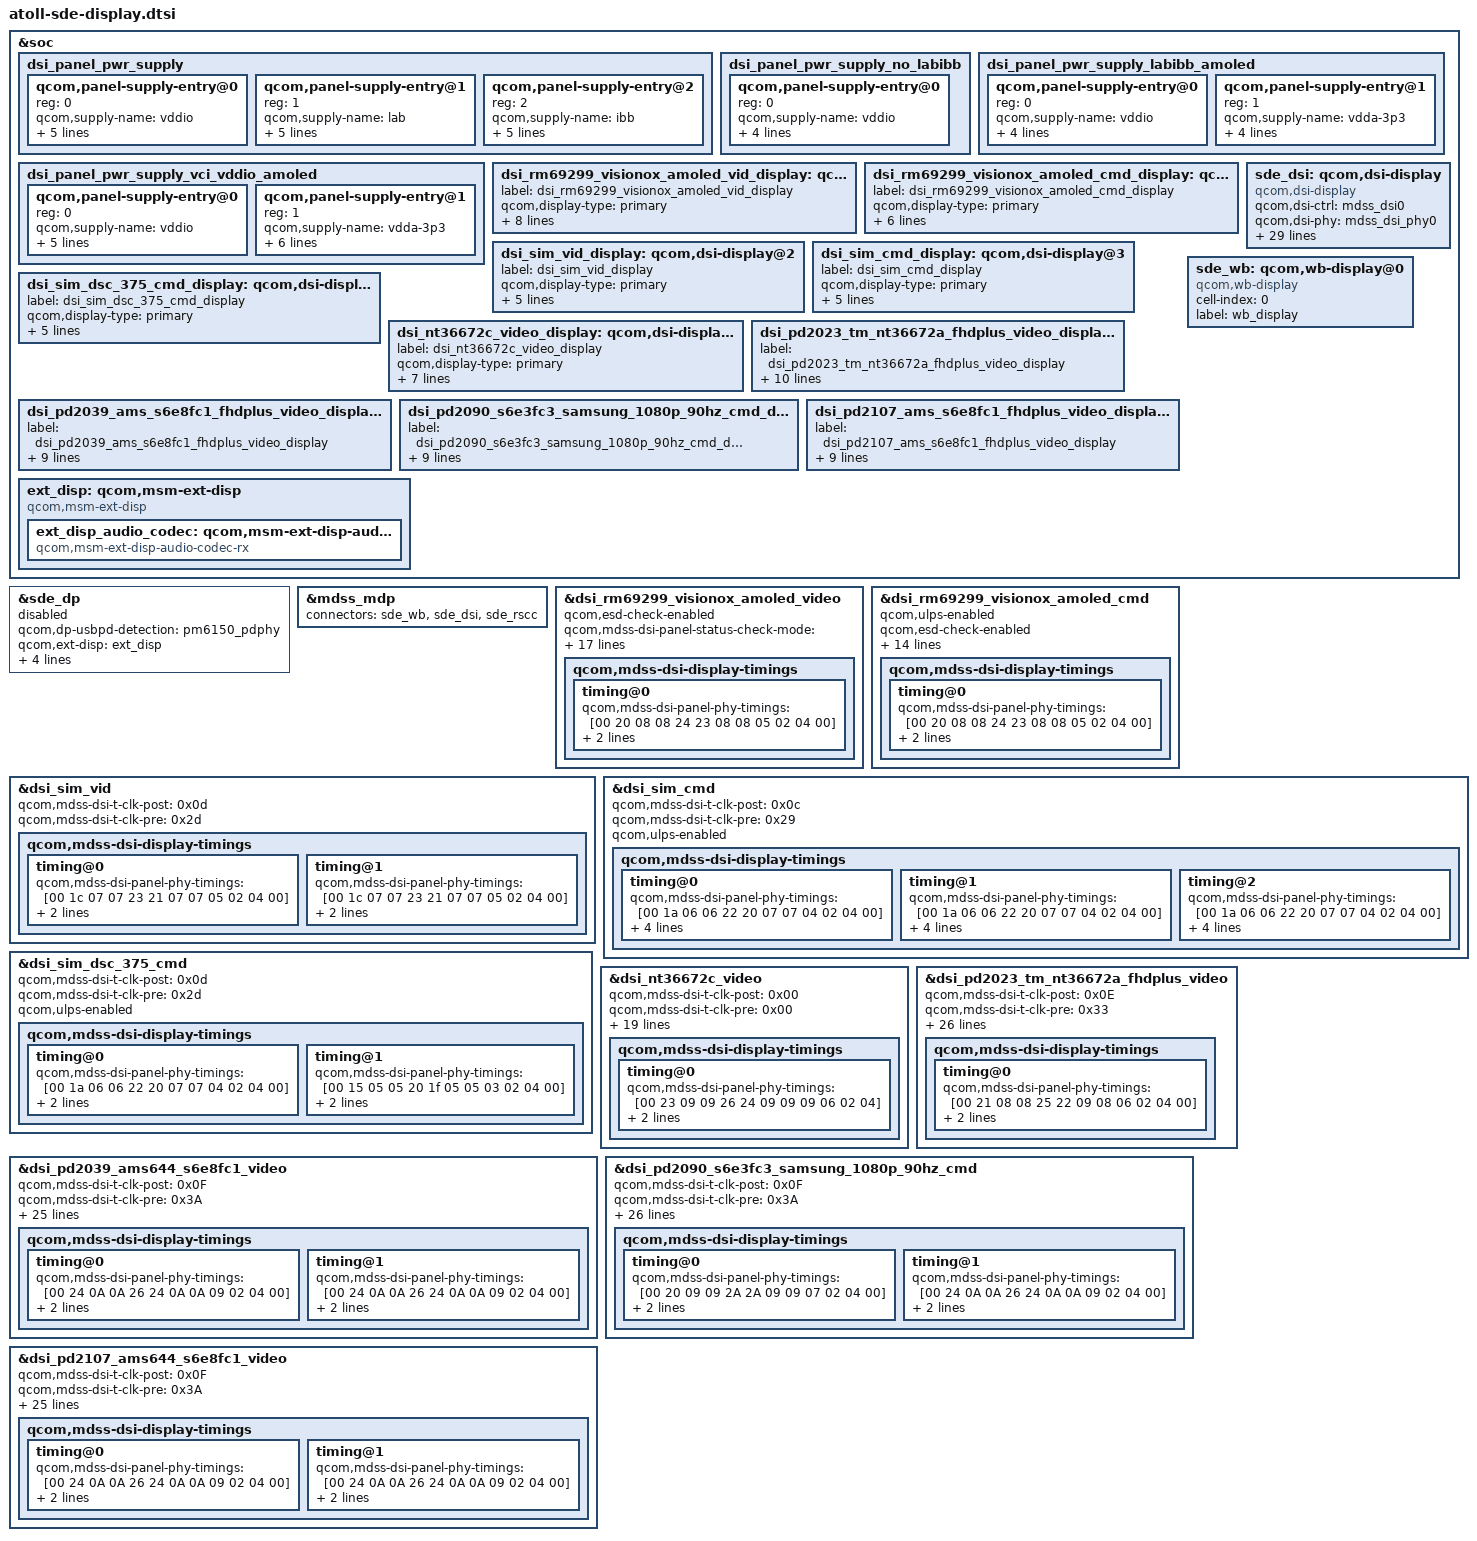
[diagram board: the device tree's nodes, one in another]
/* Copyright (c) 2019-2020, The Linux Foundation. All rights reserved.
 *
 * This program is free software; you can redistribute it and/or modify
 * it under the terms of the GNU General Public License version 2 and
 * only version 2 as published by the Free Software Foundation.
 *
 * This program is distributed in the hope that it will be useful,
 * but WITHOUT ANY WARRANTY; without even the implied warranty of
 * MERCHANTABILITY or FITNESS FOR A PARTICULAR PURPOSE.  See the
 * GNU General Public License for more details.
 */

#include "dsi-panel-rm69299-visionox-amoled-fhd-plus-video.dtsi"
#include "dsi-panel-rm69299-visionox-amoled-fhd-plus-cmd.dtsi"
#include "dsi-panel-sim-video.dtsi"
#include "dsi-panel-sim-cmd.dtsi"
#include "dsi-panel-sim-dsc375-cmd.dtsi"
#include "dsi-panel-nt36672c-fhd-plus-video.dtsi"
#include "dsi-panel-pd2023-tm-nt36672a-fhdplus-video.dtsi"
#include "dsi-panel-pd2039-ams644-s6e8fc1-1080p-video.dtsi"
#include "dsi-panel-pd2090-s6e3fc3-samsung-1080p-cmd.dtsi"
#include "dsi-panel-pd2107-ams644-s6e8fc1-1080p-video.dtsi"
#include <dt-bindings/clock/mdss-10nm-pll-clk.h>

&soc {
	dsi_panel_pwr_supply: dsi_panel_pwr_supply {
		#address-cells = <1>;
		#size-cells = <0>;

		qcom,panel-supply-entry@0 {
			reg = <0>;
			qcom,supply-name = "vddio";
			qcom,supply-min-voltage = <1800000>;
			qcom,supply-max-voltage = <1904000>;
			qcom,supply-enable-load = <32000>;
			qcom,supply-disable-load = <80>;
		};

		qcom,panel-supply-entry@1 {
			reg = <1>;
			qcom,supply-name = "lab";
			qcom,supply-min-voltage = <4600000>;
			qcom,supply-max-voltage = <6000000>;
			qcom,supply-enable-load = <100000>;
			qcom,supply-disable-load = <100>;
		};

		qcom,panel-supply-entry@2 {
			reg = <2>;
			qcom,supply-name = "ibb";
			qcom,supply-min-voltage = <4600000>;
			qcom,supply-max-voltage = <6000000>;
			qcom,supply-enable-load = <100000>;
			qcom,supply-disable-load = <100>;
			qcom,supply-post-on-sleep = <20>;
		};
	};

	dsi_panel_pwr_supply_no_labibb: dsi_panel_pwr_supply_no_labibb {
		#address-cells = <1>;
		#size-cells = <0>;

		qcom,panel-supply-entry@0 {
			reg = <0>;
			qcom,supply-name = "vddio";
			qcom,supply-min-voltage = <1800000>;
			qcom,supply-max-voltage = <1904000>;
			qcom,supply-enable-load = <32000>;
			qcom,supply-disable-load = <80>;
		};
	};

	dsi_panel_pwr_supply_labibb_amoled: dsi_panel_pwr_supply_labibb_amoled {
		#address-cells = <1>;
		#size-cells = <0>;

		qcom,panel-supply-entry@0 {
			reg = <0>;
			qcom,supply-name = "vddio";
			qcom,supply-min-voltage = <1800000>;
			qcom,supply-max-voltage = <1904000>;
			qcom,supply-enable-load = <32000>;
			qcom,supply-disable-load = <80>;
		};

		qcom,panel-supply-entry@1 {
			reg = <1>;
			qcom,supply-name = "vdda-3p3";
			qcom,supply-min-voltage = <3000000>;
			qcom,supply-max-voltage = <3000000>;
			qcom,supply-enable-load = <13200>;
			qcom,supply-disable-load = <80>;
		};
	};

	dsi_panel_pwr_supply_vci_vddio_amoled: dsi_panel_pwr_supply_vci_vddio_amoled {
		#address-cells = <1>;
		#size-cells = <0>;

		qcom,panel-supply-entry@0 {
			reg = <0>;
			qcom,supply-name = "vddio";
			qcom,supply-min-voltage = <1800000>;
			qcom,supply-max-voltage = <1800000>;
			qcom,supply-enable-load = <32000>;
			qcom,supply-disable-load = <80>;
			qcom,supply-post-on-sleep = <5>;
		};

		qcom,panel-supply-entry@1 {
			reg = <1>;
			qcom,supply-name = "vdda-3p3";
			qcom,supply-min-voltage = <3100000>;
			qcom,supply-max-voltage = <3100000>;
			qcom,supply-enable-load = <13200>;
			qcom,supply-disable-load = <80>;
			qcom,supply-post-on-sleep = <12>;
			qcom,supply-pre-off-sleep = <3>;
		};
	};


	dsi_rm69299_visionox_amoled_vid_display: qcom,dsi-display@0 {
		label = "dsi_rm69299_visionox_amoled_vid_display";
		qcom,display-type = "primary";

		qcom,dsi-ctrl-num = <0>;
		qcom,dsi-phy-num = <0>;
		qcom,dsi-select-clocks = "mux_byte_clk0", "mux_pixel_clk0",
				"src_byte_clk0", "src_pixel_clk0",
				"shadow_byte_clk0", "shadow_pixel_clk0";

		qcom,dsi-panel = <&dsi_rm69299_visionox_amoled_video>;
	};

	dsi_rm69299_visionox_amoled_cmd_display: qcom,dsi-display@1 {
		label = "dsi_rm69299_visionox_amoled_cmd_display";
		qcom,display-type = "primary";
		qcom,dsi-ctrl-num = <0>;
		qcom,dsi-phy-num = <0>;
		qcom,dsi-select-clocks = "mux_byte_clk0", "mux_pixel_clk0";
		qcom,dsi-panel = <&dsi_rm69299_visionox_amoled_cmd>;
	};

	dsi_sim_vid_display: qcom,dsi-display@2 {
		label = "dsi_sim_vid_display";
		qcom,display-type = "primary";

		qcom,dsi-ctrl-num = <0>;
		qcom,dsi-phy-num = <0>;
		qcom,dsi-select-clocks = "mux_byte_clk0", "mux_pixel_clk0";

		qcom,dsi-panel = <&dsi_sim_vid>;
	};

	dsi_sim_cmd_display: qcom,dsi-display@3 {
		label = "dsi_sim_cmd_display";
		qcom,display-type = "primary";

		qcom,dsi-ctrl-num = <0>;
		qcom,dsi-phy-num = <0>;
		qcom,dsi-select-clocks = "mux_byte_clk0", "mux_pixel_clk0";

		qcom,dsi-panel = <&dsi_sim_cmd>;
	};

	dsi_sim_dsc_375_cmd_display: qcom,dsi-display@4 {
		label = "dsi_sim_dsc_375_cmd_display";
		qcom,display-type = "primary";

		qcom,dsi-ctrl-num = <0>;
		qcom,dsi-phy-num = <0>;
		qcom,dsi-select-clocks = "mux_byte_clk0", "mux_pixel_clk0";

		qcom,dsi-panel = <&dsi_sim_dsc_375_cmd>;
	};

	dsi_nt36672c_video_display: qcom,dsi-display@5 {
		label = "dsi_nt36672c_video_display";
		qcom,display-type = "primary";

		qcom,dsi-ctrl-num = <0>;
		qcom,dsi-phy-num = <0>;

		qcom,dsi-select-clocks = "mux_byte_clk0", "mux_pixel_clk0",
					"cphy_byte_clk0", "cphy_pixel_clk0",
					"shadow_cphybyte_clk0",
					"shadow_cphypixel_clk0";
		qcom,dsi-panel = <&dsi_nt36672c_video>;
	};

	dsi_pd2023_tm_nt36672a_fhdplus_video_display: qcom,dsi-display@6 {
		label = "dsi_pd2023_tm_nt36672a_fhdplus_video_display";
		qcom,display-type = "primary";

		qcom,dsi-ctrl-num = <0>;
		qcom,dsi-phy-num = <0>;

		qcom,dsi-select-clocks = "mux_byte_clk0", "mux_pixel_clk0",
							"src_byte_clk0", "src_pixel_clk0",
							"shadow_byte_clk0", "shadow_pixel_clk0";
		qcom,dsi-panel = <&dsi_pd2023_tm_nt36672a_fhdplus_video>;
	};

	dsi_pd2039_ams_s6e8fc1_fhdplus_video_display: qcom,dsi-display@10 {
		label = "dsi_pd2039_ams_s6e8fc1_fhdplus_video_display";
		qcom,display-type = "primary";

		qcom,dsi-ctrl-num = <0>;
		qcom,dsi-phy-num = <0>;
		qcom,dsi-select-clocks = "mux_byte_clk0", "mux_pixel_clk0",
							"src_byte_clk0", "src_pixel_clk0",
							"shadow_byte_clk0", "shadow_pixel_clk0";

		qcom,dsi-panel = <&dsi_pd2039_ams644_s6e8fc1_video>;
	};
	dsi_pd2090_s6e3fc3_samsung_1080p_90hz_cmd_display: qcom,dsi-display@11 {
		label = "dsi_pd2090_s6e3fc3_samsung_1080p_90hz_cmd_display";
		qcom,display-type = "primary";

		qcom,dsi-ctrl-num = <0>;
		qcom,dsi-phy-num = <0>;
		qcom,dsi-select-clocks = "mux_byte_clk0", "mux_pixel_clk0",
							"src_byte_clk0", "src_pixel_clk0",
							"shadow_byte_clk0", "shadow_pixel_clk0";

		qcom,dsi-panel = <&dsi_pd2090_s6e3fc3_samsung_1080p_90hz_cmd>;
	};

	dsi_pd2107_ams_s6e8fc1_fhdplus_video_display: qcom,dsi-display@12 {
		label = "dsi_pd2107_ams_s6e8fc1_fhdplus_video_display";
		qcom,display-type = "primary";

		qcom,dsi-ctrl-num = <0>;
		qcom,dsi-phy-num = <0>;
		qcom,dsi-select-clocks = "mux_byte_clk0", "mux_pixel_clk0",
							"src_byte_clk0", "src_pixel_clk0",
							"shadow_byte_clk0", "shadow_pixel_clk0";

		qcom,dsi-panel = <&dsi_pd2107_ams644_s6e8fc1_video>;
	};
	sde_dsi: qcom,dsi-display {
		compatible = "qcom,dsi-display";

		qcom,dsi-ctrl = <&mdss_dsi0>;
		qcom,dsi-phy = <&mdss_dsi_phy0>;

		clocks = <&mdss_dsi0_pll BYTECLK_MUX_0_CLK>,
			 <&mdss_dsi0_pll PCLK_MUX_0_CLK>,
			 <&mdss_dsi0_pll BYTECLK_SRC_0_CLK>,
			 <&mdss_dsi0_pll PCLK_SRC_0_CLK>,
			<&mdss_dsi0_pll CPHY_BYTECLK_SRC_0_CLK>,
			<&mdss_dsi0_pll CPHY_PCLK_SRC_0_CLK>,
			 <&mdss_dsi0_pll SHADOW_BYTECLK_SRC_0_CLK>,
			 <&mdss_dsi0_pll SHADOW_PCLK_SRC_0_CLK>,
			<&mdss_dsi0_pll SHADOW_CPHY_BYTECLK_SRC_0_CLK>,
			<&mdss_dsi0_pll SHADOW_CPHY_PCLK_SRC_0_CLK>;
		clock-names = "mux_byte_clk0", "mux_pixel_clk0",
				"src_byte_clk0", "src_pixel_clk0",
				"cphy_byte_clk0", "cphy_pixel_clk0",
				"shadow_byte_clk0", "shadow_pixel_clk0",
				"shadow_cphybyte_clk0", "shadow_cphypixel_clk0";

		pinctrl-names = "panel_active", "panel_suspend";
		pinctrl-0 = <&sde_te_active &disp_pins_default>;
		pinctrl-1 = <&sde_te_suspend>;

		qcom,platform-te-gpio = <&tlmm 10 0>;
		qcom,platform-reset-gpio = <&pm6150l_gpios 3 0>;
		qcom,panel-te-source = <0>;

		vddio-supply = <&L13A>;
		vdda-3p3-supply = <&L18A>;
		lab-supply = <&lcdb_ldo_vreg>;
		ibb-supply = <&lcdb_ncp_vreg>;

		qcom,dsi-display-list =
			<&dsi_rm69299_visionox_amoled_vid_display
			&dsi_rm69299_visionox_amoled_cmd_display
			&dsi_sim_vid_display
			&dsi_sim_cmd_display
			&dsi_sim_dsc_375_cmd_display
			&dsi_nt36672c_video_display
			&dsi_pd2023_tm_nt36672a_fhdplus_video_display
			&dsi_pd2090_s6e3fc3_samsung_1080p_90hz_cmd_display
			&dsi_pd2039_ams_s6e8fc1_fhdplus_video_display
			&dsi_pd2107_ams_s6e8fc1_fhdplus_video_display>;
	};

	sde_wb: qcom,wb-display@0 {
		compatible = "qcom,wb-display";
		cell-index = <0>;
		label = "wb_display";
	};
	ext_disp: qcom,msm-ext-disp {
		compatible = "qcom,msm-ext-disp";

		ext_disp_audio_codec: qcom,msm-ext-disp-audio-codec-rx {
			compatible = "qcom,msm-ext-disp-audio-codec-rx";
		};
	};

};

&sde_dp {
	qcom,dp-usbpd-detection = <&pm6150_pdphy>;
	qcom,ext-disp = <&ext_disp>;

	qcom,usbplug-cc-gpio = <&tlmm 104 0>;

	pinctrl-name = "mdss_dp_active", "mdss_dp_sleep";
	pinctrl-0 = <&sde_dp_usbplug_cc_active>;
	pinctrl-1 = <&sde_dp_usbplug_cc_suspend>;
	status = "disabled";
};

&mdss_mdp {
	connectors = <&sde_wb &sde_dsi &sde_rscc>;
};
&dsi_panel_pwr_supply {
	qcom,panel-supply-entry@0 {
		qcom,supply-min-voltage = <1800000>;
		qcom,supply-max-voltage = <1800000>;
		qcom,supply-pre-off-sleep = <5>;
	};
	qcom,panel-supply-entry@1 {
		qcom,supply-min-voltage = <5500000>;
		qcom,supply-max-voltage = <5500000>;
		qcom,supply-post-on-sleep = <5>;
	};

	qcom,panel-supply-entry@2 {
		qcom,supply-min-voltage = <5500000>;
		qcom,supply-max-voltage = <5500000>;
		qcom,supply-post-on-sleep = <0>;
	};
};
&dsi_rm69299_visionox_amoled_video {
	qcom,esd-check-enabled;
	qcom,mdss-dsi-panel-status-check-mode = "reg_read";
	qcom,mdss-dsi-panel-status-command = [06 01 00 01 00 00 01 0a];
	qcom,mdss-dsi-panel-status-command-state = "dsi_hs_mode";
	qcom,mdss-dsi-panel-status-value = <0x9c>;
	qcom,mdss-dsi-panel-on-check-value = <0x9c>;
	qcom,mdss-dsi-panel-status-read-length = <1>;
	qcom,dsi-supported-dfps-list = <60 55 48>;
	qcom,mdss-dsi-pan-enable-dynamic-fps;
	qcom,mdss-dsi-pan-fps-update = "dfps_immediate_porch_mode_vfp";
	qcom,dsi-dyn-clk-enable;
	qcom,dsi-dyn-clk-list =
		<950938560 935089584 939051832 943014072 946976320>;
	qcom,mdss-dsi-t-clk-post = <0x0E>;
	qcom,mdss-dsi-t-clk-pre = <0x31>;
	qcom,mdss-dsi-display-timings {
		timing@0{
			qcom,mdss-dsi-panel-phy-timings = [00 20 08 08 24 23 08
				08 05 02 04 00];
			qcom,display-topology = <1 0 1>;
			qcom,default-topology-index = <0>;
		};
	};
};

&dsi_rm69299_visionox_amoled_cmd {
	qcom,ulps-enabled;
	qcom,esd-check-enabled;
	qcom,mdss-dsi-panel-status-check-mode = "reg_read";
	qcom,mdss-dsi-panel-status-command = [06 01 00 01 00 00 01 0a];
	qcom,mdss-dsi-panel-status-command-state = "dsi_hs_mode";
	qcom,mdss-dsi-panel-status-value = <0x9c>;
	qcom,mdss-dsi-panel-on-check-value = <0x9c>;
	qcom,dsi-dyn-clk-enable;
	qcom,dsi-dyn-clk-list =
		<1034259840 1017022176 1021331592 1025641008 1029950424>;
	qcom,mdss-dsi-panel-status-read-length = <1>;
	qcom,mdss-dsi-t-clk-post = <0x0E>;
	qcom,mdss-dsi-t-clk-pre = <0x31>;
	qcom,mdss-dsi-display-timings {
		timing@0{
			qcom,mdss-dsi-panel-phy-timings = [00 20 08 08 24 23 08
				08 05 02 04 00];
			qcom,display-topology = <1 0 1>;
			qcom,default-topology-index = <0>;
		};
	};
};

&dsi_sim_vid {
	qcom,mdss-dsi-t-clk-post = <0x0d>;
	qcom,mdss-dsi-t-clk-pre = <0x2d>;
	qcom,mdss-dsi-display-timings {
		timing@0{
			qcom,mdss-dsi-panel-phy-timings = [00 1c 07 07 23 21 07
				07 05 02 04 00];
			qcom,display-topology = <1 0 1>,
						<2 0 1>;
			qcom,default-topology-index = <0>;
		};
		timing@1{
			qcom,mdss-dsi-panel-phy-timings = [00 1c 07 07 23 21 07
				07 05 02 04 00];
			qcom,display-topology = <1 0 1>;
			qcom,default-topology-index = <0>;
		};
	};
};

&dsi_sim_cmd {
	qcom,mdss-dsi-t-clk-post = <0x0c>;
	qcom,mdss-dsi-t-clk-pre = <0x29>;
	qcom,ulps-enabled;
	qcom,mdss-dsi-display-timings {
		timing@0{
			qcom,mdss-dsi-panel-phy-timings = [00 1a 06 06 22 20 07
				07 04 02 04 00];
			qcom,display-topology = <1 1 1>,
						<2 2 1>;
			qcom,default-topology-index = <1>;
			qcom,panel-roi-alignment = <720 40 720 40 720 40>;
			qcom,partial-update-enabled = "single_roi";
		};

		timing@1{
			qcom,mdss-dsi-panel-phy-timings = [00 1a 06 06 22 20 07
				07 04 02 04 00];
			qcom,display-topology = <1 1 1>,
						<2 2 1>;
			qcom,default-topology-index = <1>;
			qcom,panel-roi-alignment = <540 40 540 40 540 40>;
			qcom,partial-update-enabled = "single_roi";
		};

		timing@2{
			qcom,mdss-dsi-panel-phy-timings = [00 1a 06 06 22 20 07
				07 04 02 04 00];
			qcom,display-topology = <1 1 1>,
						<2 2 1>;
			qcom,default-topology-index = <1>;
			qcom,panel-roi-alignment = <360 40 360 40 360 40>;
			qcom,partial-update-enabled = "single_roi";
		};
	};
};

&dsi_sim_dsc_375_cmd {
	qcom,mdss-dsi-t-clk-post = <0x0d>;
	qcom,mdss-dsi-t-clk-pre = <0x2d>;
	qcom,ulps-enabled;
	qcom,mdss-dsi-display-timings {
		timing@0 { /* 1080p */
			qcom,mdss-dsi-panel-phy-timings = [00 1a 06 06 22 20 07
				07 04 02 04 00];
			qcom,display-topology = <1 1 1>;
			qcom,default-topology-index = <0>;
		};
		timing@1 { /* qhd */
			qcom,mdss-dsi-panel-phy-timings = [00 15 05 05 20 1f 05
				05 03 02 04 00];
			qcom,display-topology = <1 1 1>,
						<2 2 1>, /* dsc merge */
						<2 1 1>; /* 3d mux */
			qcom,default-topology-index = <0>;
		};
	};
};

&dsi_nt36672c_video {
	qcom,mdss-dsi-t-clk-post = <0x00>;
	qcom,mdss-dsi-t-clk-pre = <0x00>;
	qcom,esd-check-enabled;
	qcom,mdss-dsi-panel-status-check-mode = "reg_read";
	qcom,mdss-dsi-panel-status-command = [06 01 00 01 00 00 01 0a];
	qcom,mdss-dsi-panel-status-command-state = "dsi_hs_mode";
	qcom,mdss-dsi-panel-status-value = <0x9c>;
	qcom,mdss-dsi-panel-on-check-value = <0x9c>;
	qcom,mdss-dsi-panel-status-read-length = <1>;
	qcom,dsi-supported-dfps-list = <60 90 50>;
	qcom,mdss-dsi-pan-enable-dynamic-fps;
	qcom,mdss-dsi-pan-fps-update = "dfps_immediate_porch_mode_vfp";
	qcom,dsi-dyn-clk-enable;
	qcom,dsi-dyn-clk-skip-timing-update;
	qcom,dsi-dyn-clk-list =
		<1052068500 1047684883 1043301259 1038917642 1034534025>;
	qcom,dsi-dyn-clk-type = "constant-fps-adjust-hfp";
	qcom,mdss-dsi-display-timings {
		timing@0{
			qcom,mdss-dsi-panel-phy-timings = [00 23 09 09 26 24 09
				09 09 06 02 04];
			qcom,display-topology = <1 0 1>;
			qcom,default-topology-index = <0>;
		};
	};
};

&dsi_pd2023_tm_nt36672a_fhdplus_video {
	qcom,mdss-dsi-t-clk-post = <0x0E>;
	qcom,mdss-dsi-t-clk-pre = <0x33>;
	qcom,esd-check-enabled;
	qcom,mdss-dsi-panel-status-check-mode = "reg_read";
	qcom,mdss-dsi-panel-status-command = [06 01 00 01 00 00 01 0a];
	qcom,mdss-dsi-panel-status-command-state = "dsi_hs_mode";
	qcom,mdss-dsi-panel-status-value = <0x9c>;
	qcom,mdss-dsi-panel-on-check-value = <0x9c>;
	qcom,mdss-dsi-panel-status-read-length = <1>;
	qcom,dsi-dyn-clk-enable;
	qcom,dsi-dyn-clk-skip-timing-update;
	qcom,dsi-dyn-clk-list = <978684120 974606272>;
	qcom,dsi-dyn-clk-type = "constant-fps-adjust-hfp";
	qcom,mdss-dsi-display-timings {
		timing@0{
			qcom,mdss-dsi-panel-phy-timings = [00 21 08 08 25 22 09
				08 06 02 04 00];
			qcom,display-topology = <1 0 1>;
			qcom,default-topology-index = <0>;
		};
	};
};

&dsi_pd2023_tm_nt36672a_fhdplus_video {
	qcom,panel-supply-entries = <&dsi_panel_pwr_supply>;
	qcom,mdss-dsi-bl-pmic-control-type = "bl_ctrl_dcs";
	qcom,mdss-dsi-bl-min-level = <1>;
	qcom,mdss-dsi-bl-max-level = <4095>;
	qcom,mdss-brightness-max-level = <4095>;
	qcom,platform-reset-gpio = <&pm6150l_gpios 3 0>;
	qcom,mdss-panel-sre;
	qcom,tddi-panel-support;
	qcom,vivo-dsi-panel-type = "tft";
	qcom,mdss-dsi-lcmid-sequence = <0x10 0x69>;
};

&dsi_pd2023_tm_nt36672a_fhdplus_video_display {
	qcom,dsi-display-active;
};

&dsi_pd2039_ams644_s6e8fc1_video {
	qcom,mdss-dsi-t-clk-post = <0x0F>;
	qcom,mdss-dsi-t-clk-pre = <0x3A>;
	//qcom,esd-check-enabled;
	qcom,mdss-dsi-panel-status-check-mode = "reg_read";
	qcom,mdss-dsi-panel-status-command = [06 01 00 01 00 00 01 0a];
	qcom,mdss-dsi-panel-status-command-state = "dsi_hs_mode";
	qcom,mdss-dsi-panel-status-value = <0x9F>;
	qcom,mdss-dsi-panel-on-check-value = <0x9F>;
	qcom,mdss-dsi-panel-status-read-length = <1>;
	qcom,mdss-dsi-display-timings {
		timing@0{
			qcom,mdss-dsi-panel-phy-timings = [00 24 0A 0A 26 24 0A
				0A 09 02 04 00];
			qcom,display-topology = <1 0 1>;
			qcom,default-topology-index = <0>;
		};
		timing@1{
			qcom,mdss-dsi-panel-phy-timings = [00 24 0A 0A 26 24 0A
				0A 09 02 04 00];
			qcom,display-topology = <1 0 1>;
			qcom,default-topology-index = <0>;
		};
	};
};

&dsi_pd2039_ams644_s6e8fc1_video {
	qcom,mdss-dsi-panel-name = "mdss_dsi_samsung_s6e8fc1_video_cmd panel";
	qcom,panel-supply-entries = <&dsi_panel_pwr_supply_vci_vddio_amoled>;
	qcom,mdss-dsi-bl-pmic-control-type = "bl_ctrl_dcs";
	qcom,mdss-dsi-bl-min-level = <1>;
	qcom,mdss-dsi-bl-max-level = <2047>;
	qcom,mdss-brightness-max-level = <2047>;
	qcom,mdss-dsi-bl-default-level = <573>;
	qcom,platform-te-gpio = <&tlmm 10 0>;
	qcom,platform-reset-gpio = <&pm6150l_gpios 3 0>;
	qcom,mdss-dsi-panel-id = <0x20>;
	qcom,mdss-dsi-project-name = "pd2039";
	qcom,mdss-dsi-lcmid-sequence = <0x21 0x4E>, <0x21 0x41>;
};

&dsi_pd2090_s6e3fc3_samsung_1080p_90hz_cmd {
	qcom,mdss-dsi-t-clk-post = <0x0F>;
	qcom,mdss-dsi-t-clk-pre = <0x3A>;
	//qcom,esd-check-enabled;
	qcom,mdss-dsi-panel-status-check-mode = "reg_read";
	qcom,mdss-dsi-panel-status-command = [06 01 00 01 00 00 01 0a];
	qcom,mdss-dsi-panel-status-command-state = "dsi_hs_mode";
	qcom,mdss-dsi-panel-status-value = <0x9F>;
	qcom,mdss-dsi-panel-on-check-value = <0x9F>;
	qcom,mdss-dsi-panel-status-read-length = <1>;
	qcom,mdss-dsi-display-timings {
		timing@0{
			qcom,mdss-dsi-panel-phy-timings = [00 20 09 09 2A 2A 09
				09 07 02 04 00];
			qcom,display-topology = <1 0 1>;
			qcom,default-topology-index = <0>;
		};
		timing@1{
			qcom,mdss-dsi-panel-phy-timings = [00 24 0A 0A 26 24 0A
				0A 09 02 04 00];
			qcom,display-topology = <1 0 1>;
			qcom,default-topology-index = <0>;
		};
	};
};

&dsi_pd2090_s6e3fc3_samsung_1080p_90hz_cmd {
	qcom,mdss-dsi-panel-name = "mdss_dsi_samsung_s6e8fc1_video_cmd 2090panel";
	qcom,panel-supply-entries = <&dsi_panel_pwr_supply_vci_vddio_amoled>;
	qcom,mdss-dsi-bl-pmic-control-type = "bl_ctrl_dcs";
	qcom,mdss-dsi-bl-min-level = <1>;
	qcom,mdss-dsi-bl-max-level = <2047>;
	qcom,mdss-brightness-max-level = <2047>;
	qcom,mdss-dsi-bl-default-level = <1573>;
	qcom,platform-te-gpio = <&tlmm 10 0>;
	qcom,platform-vddr-en-gpio = <&tlmm 118 0>;
	qcom,platform-reset-gpio = <&pm6150l_gpios 3 0>;
	qcom,mdss-dsi-panel-id = <0x24>;
	qcom,mdss-dsi-project-name = "pd2090";
	qcom,mdss-dsi-lcmid-sequence = <0x24 0x4E>, <0x24 0x4F>;
};

&dsi_pd2107_ams644_s6e8fc1_video {
	qcom,mdss-dsi-t-clk-post = <0x0F>;
	qcom,mdss-dsi-t-clk-pre = <0x3A>;
	//qcom,esd-check-enabled;
	qcom,mdss-dsi-panel-status-check-mode = "reg_read";
	qcom,mdss-dsi-panel-status-command = [06 01 00 01 00 00 01 0a];
	qcom,mdss-dsi-panel-status-command-state = "dsi_hs_mode";
	qcom,mdss-dsi-panel-status-value = <0x9F>;
	qcom,mdss-dsi-panel-on-check-value = <0x9F>;
	qcom,mdss-dsi-panel-status-read-length = <1>;
	qcom,mdss-dsi-display-timings {
		timing@0{
			qcom,mdss-dsi-panel-phy-timings = [00 24 0A 0A 26 24 0A
				0A 09 02 04 00];
			qcom,display-topology = <1 0 1>;
			qcom,default-topology-index = <0>;
		};
		timing@1{
			qcom,mdss-dsi-panel-phy-timings = [00 24 0A 0A 26 24 0A
				0A 09 02 04 00];
			qcom,display-topology = <1 0 1>;
			qcom,default-topology-index = <0>;
		};
	};
};

&dsi_pd2107_ams644_s6e8fc1_video {
	qcom,mdss-dsi-panel-name = "mdss_dsi_samsung_s6e8fc1_video_cmd panel";
	qcom,panel-supply-entries = <&dsi_panel_pwr_supply_vci_vddio_amoled>;
	qcom,mdss-dsi-bl-pmic-control-type = "bl_ctrl_dcs";
	qcom,mdss-dsi-bl-min-level = <1>;
	qcom,mdss-dsi-bl-max-level = <2047>;
	qcom,mdss-brightness-max-level = <2047>;
	qcom,mdss-dsi-bl-default-level = <573>;
	qcom,platform-te-gpio = <&tlmm 10 0>;
	qcom,platform-reset-gpio = <&pm6150l_gpios 3 0>;
	qcom,mdss-dsi-panel-id = <0x20>;
	qcom,mdss-dsi-project-name = "pd2107";
	qcom,mdss-dsi-lcmid-sequence = <0x21 0x4E>, <0x21 0x41>;
};
